# FUSB15200 register map
Vendor: ON Semiconductor; Series: FUSB15200; File version: 1.0
CPU: CM0+ r1p0, little endian, no MPU, no FPU, 3 interrupt priority bits
Registers are 32-bit, read-write, reset 0x0 unless marked. A register's access mark holds for its fields unless they carry their own. Offsets are from the block's base; [hi:lo] are bit positions.

## DMA
Base 0x40A00000
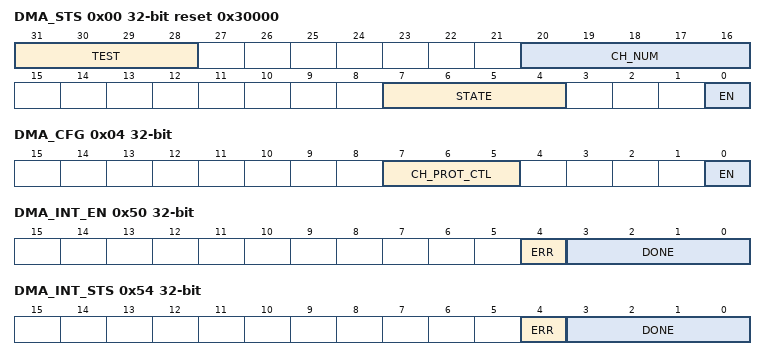
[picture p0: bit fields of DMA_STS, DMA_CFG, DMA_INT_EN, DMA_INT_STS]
0x00 DMA_STS reset 0x30000 (reset mask 0x10010011)
  [31:28] TEST ro, [20:16] CH_NUM ro, [7:4] STATE ro, [0] EN ro
0x04 DMA_CFG (reset mask 0x21)
  [7:5] CH_PROT_CTL wo, [0] EN wo
0x08 DMA_CTL_BASE_PTR (reset mask 0x80)
  [31:7] CTL_BASE_PTR
0x0C DMA_ATL_CTL_BASE_PTR reset 0x40 (reset mask 0x1)
  [31:0] ALT_CTL_BASE_PTR ro
0x10 DMA_WAIT_ON_REQ_STS reset 0xF (reset mask 0x1)
  [3:0] WAIT_ON_REQ_STS ro
0x14 DMA_SW_REQ (reset mask 0x1)
  [3:0] SW_REQ wo
0x18 DMA_USE_BURST_SET (reset mask 0x1)
  [3:0] USE_BURST_SET
0x1C DMA_USE_BURST_CLR (reset mask 0x1)
  [3:0] USE_BURST_CLR wo
0x20 DMA_REQ_MASK_SET (reset mask 0x1)
  [3:0] REQ_MASK_SET
0x24 DMA_REQ_MASK_CLR (reset mask 0x1)
  [3:0] REQ_MASK_CLR wo
0x28 DMA_EN_SET (reset mask 0x1)
  [3:0] EN_SET
0x2C DMA_EN_CLR (reset mask 0x1)
  [3:0] EN_CLR wo
0x30 DMA_PRI_ALT_SEL_SET (reset mask 0x1)
  [3:0] PRI_ALT_SEL_SET
0x34 DMA_PRI_ALT_CLR (reset mask 0x1)
  [3:0] PRI_ALT_CLR wo
0x38 DMA_PRIO_SET (reset mask 0x1)
  [3:0] PRIO_SET
0x3C DMA_PRIO_CLR (reset mask 0x1)
  [3:0] PRIO_CLR wo
0x4C DMA_ERR_CLR
  [0] ERR_CLR
0x50 DMA_INT_EN (reset mask 0x11)
  [4] ERR, [3:0] DONE
0x54 DMA_INT_STS (reset mask 0x11)
  [4] ERR wo, [3:0] DONE wo

## I2C_Port_1
Base 0x40C00000
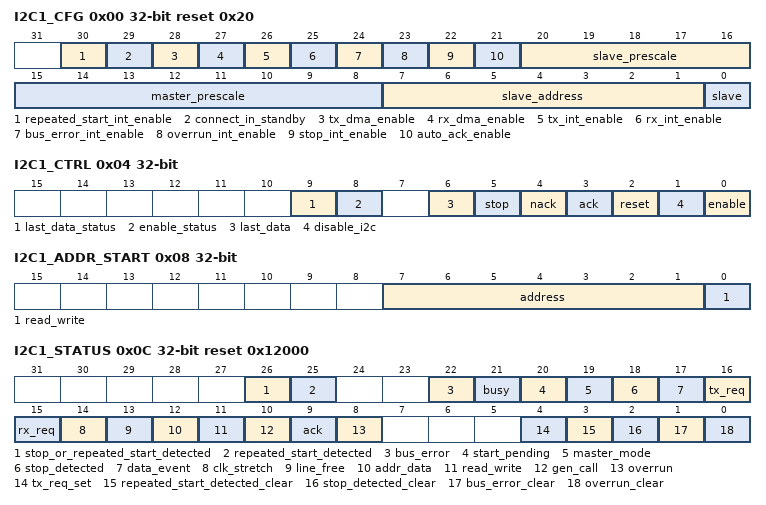
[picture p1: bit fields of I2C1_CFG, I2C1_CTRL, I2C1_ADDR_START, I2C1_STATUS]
0x00 I2C1_CFG reset 0x20 (reset mask 0x7FE10103)
  [30] repeated_start_int_enable, [29] connect_in_standby, [28] tx_dma_enable, [27] rx_dma_enable, [26] tx_int_enable, [25] rx_int_enable, [24] bus_error_int_enable, [23] overrun_int_enable, [22] stop_int_enable, [21] auto_ack_enable, [20:16] slave_prescale, [15:8] master_prescale, [7:1] slave_address, [0] slave
0x04 I2C1_CTRL
  [9] last_data_status ro, [8] enable_status ro, [6] last_data wo, [5] stop wo, [4] nack wo, [3] ack wo, [2] reset wo, [1] disable_i2c wo, [0] enable wo
0x08 I2C1_ADDR_START (reset mask 0x3)
  [7:1] address, [0] read_write
0x0C I2C1_STATUS reset 0x12000
  [26] stop_or_repeated_start_detected ro, [25] repeated_start_detected ro, [22] bus_error ro, [21] busy ro, [20] start_pending ro, [19] master_mode ro, [18] stop_detected ro, [17] data_event ro, [16] tx_req ro, [15] rx_req ro, [14] clk_stretch ro, [13] line_free ro, [12] addr_data ro, [11] read_write ro, [10] gen_call ro, [9] ack ro, [8] overrun ro, [4] tx_req_set wo, [3] repeated_start_detected_clear wo, [2] stop_detected_clear wo, [1] bus_error_clear wo, [0] overrun_clear wo
0x10 I2C1_TX_DATA (reset mask 0x1)
  [7:0] tx_data
0x14 I2C1_RX_DATA (reset mask 0x1)
  [7:0] rx_data ro
0x18 I2C1_RX_DATA_MIRROR (reset mask 0x1)
  [7:0] rx_data ro
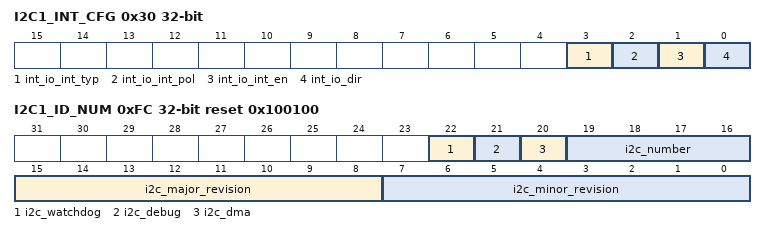
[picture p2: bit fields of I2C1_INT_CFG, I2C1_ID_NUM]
0x30 I2C1_INT_CFG
  [3] int_io_int_typ, [2] int_io_int_pol, [1] int_io_int_en, [0] int_io_dir
0x34 I2C1_INT_OUT reset 0x1
  [0] int_out
0x38 I2C1_INT_IN
  [0] int_in ro
0x3C I2C1_INT_STS
  [0] int_sts wo
0xFC I2C1_ID_NUM reset 0x100100 (reset mask 0x710101)
  [22] i2c_watchdog ro, [21] i2c_debug ro, [20] i2c_dma ro, [19:16] i2c_number ro, [15:8] i2c_major_revision ro, [7:0] i2c_minor_revision ro

## I2C_Port_2
Base 0x40D00000
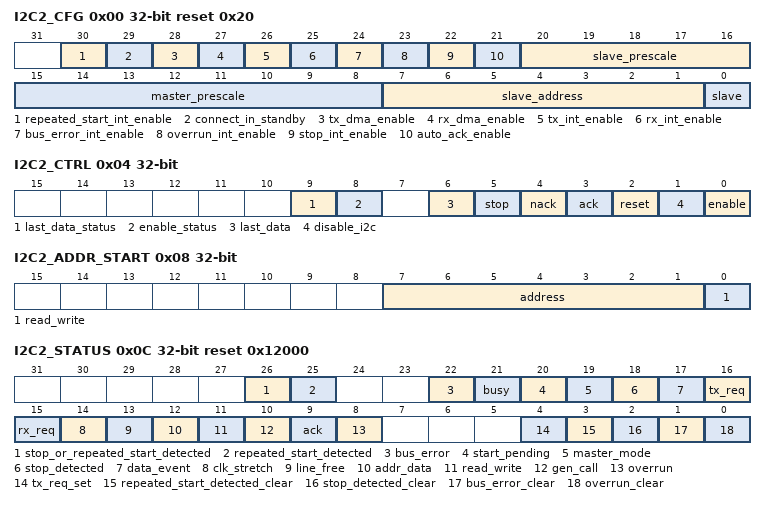
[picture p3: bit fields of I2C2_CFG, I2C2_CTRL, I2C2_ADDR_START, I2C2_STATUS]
0x00 I2C2_CFG reset 0x20 (reset mask 0x7FE10103)
  [30] repeated_start_int_enable, [29] connect_in_standby, [28] tx_dma_enable, [27] rx_dma_enable, [26] tx_int_enable, [25] rx_int_enable, [24] bus_error_int_enable, [23] overrun_int_enable, [22] stop_int_enable, [21] auto_ack_enable, [20:16] slave_prescale, [15:8] master_prescale, [7:1] slave_address, [0] slave
0x04 I2C2_CTRL
  [9] last_data_status ro, [8] enable_status ro, [6] last_data wo, [5] stop wo, [4] nack wo, [3] ack wo, [2] reset wo, [1] disable_i2c wo, [0] enable wo
0x08 I2C2_ADDR_START (reset mask 0x3)
  [7:1] address, [0] read_write
0x0C I2C2_STATUS reset 0x12000
  [26] stop_or_repeated_start_detected ro, [25] repeated_start_detected ro, [22] bus_error ro, [21] busy ro, [20] start_pending ro, [19] master_mode ro, [18] stop_detected ro, [17] data_event ro, [16] tx_req ro, [15] rx_req ro, [14] clk_stretch ro, [13] line_free ro, [12] addr_data ro, [11] read_write ro, [10] gen_call ro, [9] ack ro, [8] overrun ro, [4] tx_req_set wo, [3] repeated_start_detected_clear wo, [2] stop_detected_clear wo, [1] bus_error_clear wo, [0] overrun_clear wo
0x10 I2C2_TX_DATA (reset mask 0x1)
  [7:0] tx_data
0x14 I2C2_RX_DATA (reset mask 0x1)
  [7:0] rx_data ro
0x18 I2C2_RX_DATA_MIRROR (reset mask 0x1)
  [7:0] rx_data ro
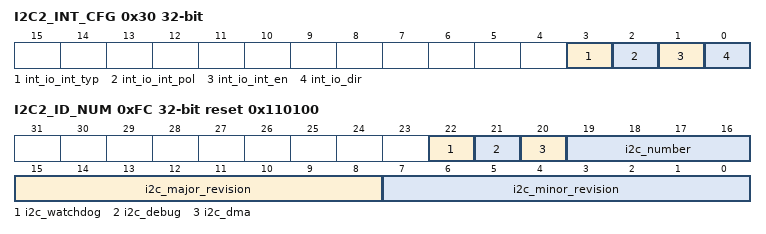
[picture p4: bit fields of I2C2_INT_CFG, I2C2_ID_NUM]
0x30 I2C2_INT_CFG
  [3] int_io_int_typ, [2] int_io_int_pol, [1] int_io_int_en, [0] int_io_dir
0x34 I2C2_INT_OUT reset 0x1
  [0] int_out
0x38 I2C2_INT_IN
  [0] int_in ro
0x3C I2C2_INT_STS
  [0] int_sts wo
0xFC I2C2_ID_NUM reset 0x110100 (reset mask 0x710101)
  [22] i2c_watchdog ro, [21] i2c_debug ro, [20] i2c_dma ro, [19:16] i2c_number ro, [15:8] i2c_major_revision ro, [7:0] i2c_minor_revision ro
